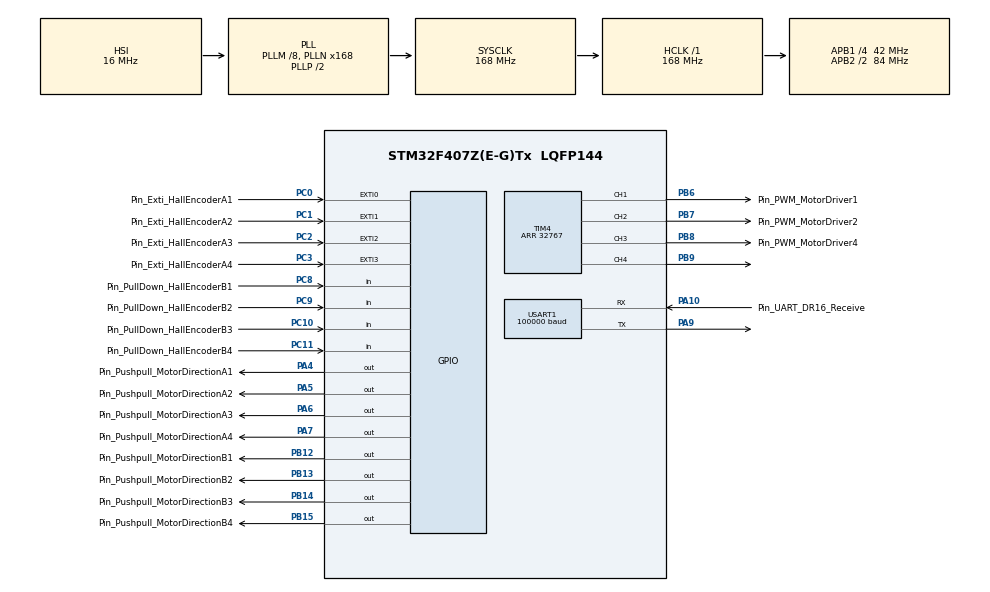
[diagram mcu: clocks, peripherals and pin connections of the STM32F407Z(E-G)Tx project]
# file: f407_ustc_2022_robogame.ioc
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Dma.Request0=USART1_RX
Dma.USART1_RX.0.Direction=DMA_PERIPH_TO_MEMORY
Dma.USART1_RX.0.FIFOMode=DMA_FIFOMODE_DISABLE
Dma.USART1_RX.0.Instance=DMA2_Stream2
Dma.USART1_RX.0.MemDataAlignment=DMA_MDATAALIGN_BYTE
Dma.USART1_RX.0.MemInc=DMA_MINC_ENABLE
Dma.USART1_RX.0.Mode=DMA_CIRCULAR
Dma.USART1_RX.0.PeriphDataAlignment=DMA_PDATAALIGN_BYTE
Dma.USART1_RX.0.PeriphInc=DMA_PINC_DISABLE
Dma.USART1_RX.0.Priority=DMA_PRIORITY_LOW
Mcu.Family=STM32F4
Mcu.Name=STM32F407Z(E-G)Tx
Mcu.Package=LQFP144
NVIC.DMA2_Stream2_IRQn=true\:0\:0\:false\:false\:true\:false\:true
NVIC.EXTI0_IRQn=true\:0\:0\:false\:false\:true\:true\:true
NVIC.EXTI1_IRQn=true\:0\:0\:false\:false\:true\:true\:true
NVIC.EXTI2_IRQn=true\:0\:0\:false\:false\:true\:true\:true
NVIC.EXTI3_IRQn=true\:0\:0\:false\:false\:true\:true\:true
NVIC.PriorityGroup=NVIC_PRIORITYGROUP_4
NVIC.TIM5_IRQn=true\:0\:0\:false\:false\:true\:true\:true
NVIC.USART1_IRQn=true\:0\:0\:false\:false\:true\:true\:true
PA10.GPIO_Label=Pin_UART_DR16_Receive
PA10.Mode=Asynchronous
PA10.Signal=USART1_RX
PA13.Mode=Serial_Wire
PA13.Signal=SYS_JTMS-SWDIO
PA14.Mode=Serial_Wire
PA14.Signal=SYS_JTCK-SWCLK
PA4.GPIO_Label=Pin_Pushpull_MotorDirectionA1
PA4.Signal=GPIO_Output
PA5.GPIO_Label=Pin_Pushpull_MotorDirectionA2
PA5.Signal=GPIO_Output
PA6.GPIO_Label=Pin_Pushpull_MotorDirectionA3
PA6.Signal=GPIO_Output
PA7.GPIO_Label=Pin_Pushpull_MotorDirectionA4
PA7.Signal=GPIO_Output
PA9.Mode=Asynchronous
PA9.Signal=USART1_TX
PB12.GPIO_Label=Pin_Pushpull_MotorDirectionB1
PB12.Signal=GPIO_Output
PB13.GPIO_Label=Pin_Pushpull_MotorDirectionB2
PB13.Signal=GPIO_Output
PB14.GPIO_Label=Pin_Pushpull_MotorDirectionB3
PB14.Signal=GPIO_Output
PB15.GPIO_Label=Pin_Pushpull_MotorDirectionB4
PB15.Signal=GPIO_Output
PB6.GPIO_Label=Pin_PWM_MotorDriver1
PB6.Signal=S_TIM4_CH1
PB7.GPIO_Label=Pin_PWM_MotorDriver2
PB7.Signal=S_TIM4_CH2
PB8.GPIO_Label=Pin_PWM_MotorDriver4
PB8.Signal=S_TIM4_CH3
PB9.Signal=S_TIM4_CH4
PC0.GPIO_Label=Pin_Exti_HallEncoderA1
PC0.GPIO_PuPd=GPIO_PULLDOWN
PC0.Signal=GPXTI0
PC1.GPIO_Label=Pin_Exti_HallEncoderA2
PC1.GPIO_PuPd=GPIO_PULLDOWN
PC1.Signal=GPXTI1
PC10.GPIO_Label=Pin_PullDown_HallEncoderB3
PC10.GPIO_PuPd=GPIO_PULLDOWN
PC10.Signal=GPIO_Input
PC11.GPIO_Label=Pin_PullDown_HallEncoderB4
PC11.GPIO_PuPd=GPIO_PULLDOWN
PC11.Signal=GPIO_Input
PC14-OSC32_IN.Mode=LSE-External-Oscillator
PC14-OSC32_IN.Signal=RCC_OSC32_IN
PC15-OSC32_OUT.Mode=LSE-External-Oscillator
PC15-OSC32_OUT.Signal=RCC_OSC32_OUT
PC2.GPIO_Label=Pin_Exti_HallEncoderA3
PC2.GPIO_PuPd=GPIO_PULLDOWN
PC2.Signal=GPXTI2
PC3.GPIO_Label=Pin_Exti_HallEncoderA4
PC3.GPIO_PuPd=GPIO_PULLDOWN
PC3.Signal=GPXTI3
PC8.GPIO_Label=Pin_PullDown_HallEncoderB1
PC8.GPIO_PuPd=GPIO_PULLDOWN
PC8.Signal=GPIO_Input
PC9.GPIO_Label=Pin_PullDown_HallEncoderB2
PC9.GPIO_PuPd=GPIO_PULLDOWN
PC9.Signal=GPIO_Input
PH0-OSC_IN.Mode=HSE-External-Oscillator
PH0-OSC_IN.Signal=RCC_OSC_IN
PH1-OSC_OUT.Mode=HSE-External-Oscillator
PH1-OSC_OUT.Signal=RCC_OSC_OUT
ProjectManager.HeapSize=0x200
ProjectManager.StackSize=0x400
ProjectManager.TargetToolchain=MDK-ARM V5.32
RCC.48MHZClocksFreq_Value=84000000
RCC.AHBFreq_Value=168000000
RCC.APB1CLKDivider=RCC_HCLK_DIV4
RCC.APB1Freq_Value=42000000
RCC.APB1TimFreq_Value=84000000
RCC.APB2CLKDivider=RCC_HCLK_DIV2
RCC.APB2Freq_Value=84000000
RCC.APB2TimFreq_Value=168000000
RCC.CortexFreq_Value=168000000
RCC.HCLKFreq_Value=168000000
RCC.HSE_VALUE=25000000
RCC.HSI_VALUE=16000000
RCC.PLLM=8
RCC.PLLN=168
RCC.SYSCLKFreq_VALUE=168000000
RCC.SYSCLKSource=RCC_SYSCLKSOURCE_PLLCLK
RCC.VCOOutputFreq_Value=336000000
SH.S_TIM4_CH1.0=TIM4_CH1,PWM Generation1 CH1
SH.S_TIM4_CH2.0=TIM4_CH2,PWM Generation2 CH2
SH.S_TIM4_CH3.0=TIM4_CH3,PWM Generation3 CH3
SH.S_TIM4_CH4.0=TIM4_CH4,PWM Generation4 CH4
TIM4.AutoReloadPreload=TIM_AUTORELOAD_PRELOAD_ENABLE
TIM4.Channel-PWM\ Generation1\ CH1=TIM_CHANNEL_1
TIM4.Channel-PWM\ Generation2\ CH2=TIM_CHANNEL_2
TIM4.Channel-PWM\ Generation3\ CH3=TIM_CHANNEL_3
TIM4.Channel-PWM\ Generation4\ CH4=TIM_CHANNEL_4
TIM4.Period=32767
TIM5.AutoReloadPreload=TIM_AUTORELOAD_PRELOAD_ENABLE
TIM5.Period=9999
TIM5.Prescaler=41
USART1.BaudRate=100000
USART1.Mode=MODE_RX
USART1.Parity=PARITY_EVEN
USART1.VirtualMode=VM_ASYNC
USART1.WordLength=WORDLENGTH_9B
VP_TIM5_VS_ClockSourceINT.Mode=Internal
board=custom

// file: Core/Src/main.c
/* USER CODE BEGIN Header */
/**
  ******************************************************************************
  * @file           : main.c
  * @brief          : Main program body
  ******************************************************************************
  * @attention
  *
  * <h2><center>&copy; Copyright (c) 2022 STMicroelectronics.
  * All rights reserved.</center></h2>
  *
  * This software component is licensed by ST under BSD 3-Clause license,
  * the "License"; You may not use this file except in compliance with the
  * License. You may obtain a copy of the License at:
  *                        opensource.org/licenses/BSD-3-Clause
  *
  ******************************************************************************
  */
/* USER CODE END Header */
#include "main.h"
#include "dma.h"
#include "tim.h"
#include "usart.h"
#include "gpio.h"

/* USER CODE BEGIN Includes */

#include "Chassis.hpp"

/* USER CODE END Includes */

/* USER CODE BEGIN PV */

Class_Chassis Chassis;

/* USER CODE END PV */

void SystemClock_Config(void);

int main(void)
{

  /* MCU Configuration--------------------------------------------------------*/

  /* Reset of all peripherals, Initializes the Flash interface and the Systick. */
  HAL_Init();

  /* Configure the system clock */
  SystemClock_Config();

  /* Initialize all configured peripherals */
  MX_GPIO_Init();
  MX_DMA_Init();
  MX_TIM4_Init();
  MX_TIM5_Init();
  MX_USART1_UART_Init();
  /* USER CODE BEGIN 2 */

  //底盘初始化
  Chassis.Init(CHASSIS_MOTOR_PWM_DRIVER_TIM, CHASSIS_MOTOR_CALCULATE_TIM);
  Chassis.Set_Control_Method(Control_Method_OPENLOOP);

  //使能计算时钟
  HAL_TIM_Base_Start_IT(&CHASSIS_MOTOR_CALCULATE_TIM);

  //使能遥控器DMA-UART
  HAL_UART_Receive_DMA(&CHASSIS_DR16_CONTROL_UART, Chassis.DR16.Pack, DR16_PACK_LENGTH);

  /* USER CODE END 2 */

  /* Infinite loop */
  /* USER CODE BEGIN WHILE */

  // SpeedTypeDef v_front=
  // {
  //   0, 1, 0
  // };

  // SpeedTypeDef v_back=
  // {
  //   0, -1, 0
  // };

  // SpeedTypeDef v_right=
  // {
  //   1, 0, 0
  // };

  // SpeedTypeDef v_left=
  // {
  //   -1, 0, 0
  // };

  // SpeedTypeDef v_rotate=
  // {
  //   0, 0, 2
  // };

  // SpeedTypeDef v_crotate=
  // {
  //   0, 0, -2
  // };

  // SpeedTypeDef v_stop=
  // {
  //   0, 0, 0
  // };

  // Chassis.Set_Velocity(v_stop);
  // HAL_Delay(1500);

  while (1)
  {
    // Chassis.Set_Velocity(v_front);
    // HAL_Delay(1000);
    // Chassis.Set_Velocity(v_right);
    // HAL_Delay(1000);
    // Chassis.Set_Velocity(v_rotate);
    // HAL_Delay(1000);
    // Chassis.Set_Velocity(v_crotate);
    // HAL_Delay(1000);
    // Chassis.Set_Velocity(v_left);
    // HAL_Delay(1000);
    // Chassis.Set_Velocity(v_back);
    // HAL_Delay(1000);

    /* USER CODE END WHILE */

  }
}

void SystemClock_Config(void)
{
  RCC_OscInitTypeDef RCC_OscInitStruct = {0};
  RCC_ClkInitTypeDef RCC_ClkInitStruct = {0};

  /** Configure the main internal regulator output voltage
  */
  __HAL_RCC_PWR_CLK_ENABLE();
  __HAL_PWR_VOLTAGESCALING_CONFIG(PWR_REGULATOR_VOLTAGE_SCALE1);
  /** Initializes the RCC Oscillators according to the specified parameters
  * in the RCC_OscInitTypeDef structure.
  */
  RCC_OscInitStruct.OscillatorType = RCC_OSCILLATORTYPE_HSI;
  RCC_OscInitStruct.HSIState = RCC_HSI_ON;
  RCC_OscInitStruct.HSICalibrationValue = RCC_HSICALIBRATION_DEFAULT;
  RCC_OscInitStruct.PLL.PLLState = RCC_PLL_ON;
  RCC_OscInitStruct.PLL.PLLSource = RCC_PLLSOURCE_HSI;
  RCC_OscInitStruct.PLL.PLLM = 8;
  RCC_OscInitStruct.PLL.PLLN = 168;
  RCC_OscInitStruct.PLL.PLLP = RCC_PLLP_DIV2;
  RCC_OscInitStruct.PLL.PLLQ = 4;
  if (HAL_RCC_OscConfig(&RCC_OscInitStruct) != HAL_OK)
  {
    Error_Handler();
  }
  /** Initializes the CPU, AHB and APB buses clocks
  */
  RCC_ClkInitStruct.ClockType = RCC_CLOCKTYPE_HCLK|RCC_CLOCKTYPE_SYSCLK
                              |RCC_CLOCKTYPE_PCLK1|RCC_CLOCKTYPE_PCLK2;
  RCC_ClkInitStruct.SYSCLKSource = RCC_SYSCLKSOURCE_PLLCLK;
  RCC_ClkInitStruct.AHBCLKDivider = RCC_SYSCLK_DIV1;
  RCC_ClkInitStruct.APB1CLKDivider = RCC_HCLK_DIV4;
  RCC_ClkInitStruct.APB2CLKDivider = RCC_HCLK_DIV2;

  if (HAL_RCC_ClockConfig(&RCC_ClkInitStruct, FLASH_LATENCY_5) != HAL_OK)
  {
    Error_Handler();
  }
}

void Error_Handler(void)
{
  __disable_irq();
  while (1)
  {
  }
}

/************************ (C) COPYRIGHT STMicroelectronics *****END OF FILE****/
